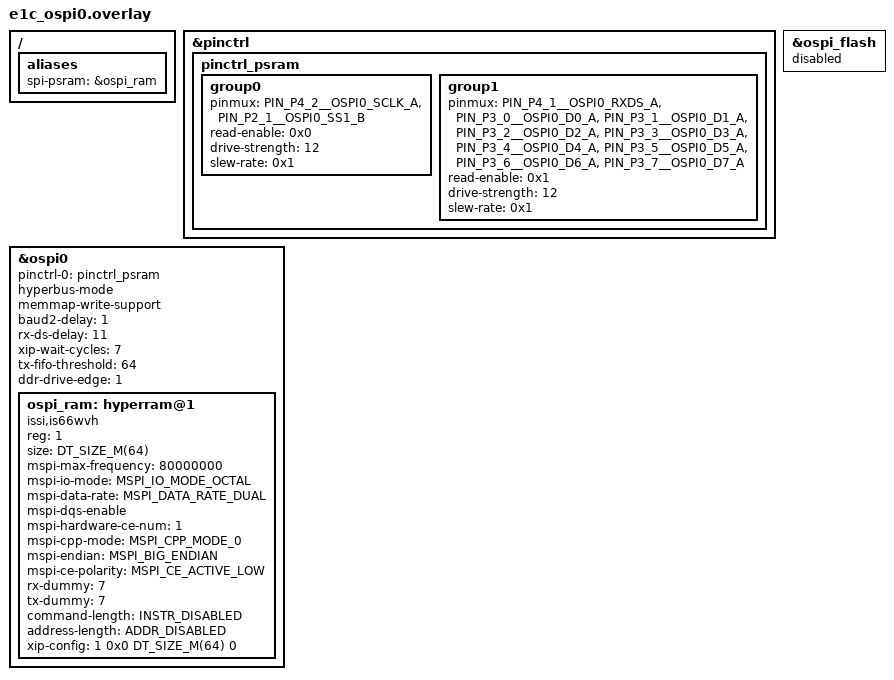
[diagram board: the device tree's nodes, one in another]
/* Copyright (C) 2026 Alif Semiconductor - All Rights Reserved.
 * Use, distribution and modification of this code is permitted under the
 * terms stated in the Alif Semiconductor Software License Agreement
 */

/*
 * Enable the ISSI IS66WVH HyperRAM connected to OSPI0 on E1C boards.
 */

/ {
	aliases {
		spi-psram = &ospi_ram;
	};
};

&pinctrl {
	pinctrl_psram: pinctrl_psram {
		group0 {
			pinmux = <PIN_P4_2__OSPI0_SCLK_A>,
				 <PIN_P2_1__OSPI0_SS1_B>;
			read-enable = <0x0>;
			drive-strength = <12>;
			slew-rate = <0x1>;
		};

		group1 {
			pinmux = <PIN_P4_1__OSPI0_RXDS_A>,
				 <PIN_P3_0__OSPI0_D0_A>,
				 <PIN_P3_1__OSPI0_D1_A>,
				 <PIN_P3_2__OSPI0_D2_A>,
				 <PIN_P3_3__OSPI0_D3_A>,
				 <PIN_P3_4__OSPI0_D4_A>,
				 <PIN_P3_5__OSPI0_D5_A>,
				 <PIN_P3_6__OSPI0_D6_A>,
				 <PIN_P3_7__OSPI0_D7_A>;
			read-enable = <0x1>;
			drive-strength = <12>;
			slew-rate = <0x1>;
		};
	};
};

&ospi_flash {
	status = "disabled";
};

&ospi0 {
	pinctrl-0 = <&pinctrl_psram>;
	pinctrl-names = "default";
	hyperbus-mode;
	memmap-write-support;
	baud2-delay = <1>;
	rx-ds-delay = <11>;
	xip-wait-cycles = <7>;
	tx-fifo-threshold = <64>;
	ddr-drive-edge = <1>;
	status = "okay";

	ospi_ram: hyperram@1 {
		compatible = "issi,is66wvh";
		reg = <1>;
		size = <DT_SIZE_M(64)>;
		mspi-max-frequency = <80000000>;
		mspi-io-mode = "MSPI_IO_MODE_OCTAL";
		mspi-data-rate = "MSPI_DATA_RATE_DUAL";
		mspi-dqs-enable;
		mspi-hardware-ce-num = <1>;
		mspi-cpp-mode = "MSPI_CPP_MODE_0";
		mspi-endian = "MSPI_BIG_ENDIAN";
		mspi-ce-polarity = "MSPI_CE_ACTIVE_LOW";
		rx-dummy = <7>;
		tx-dummy = <7>;
		command-length = "INSTR_DISABLED";
		address-length = "ADDR_DISABLED";
		xip-config = <1 0x0 DT_SIZE_M(64) 0>;
		status = "okay";
	};
};
